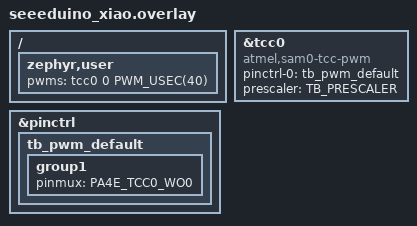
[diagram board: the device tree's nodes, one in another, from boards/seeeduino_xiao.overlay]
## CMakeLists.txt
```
# SPDX-License-Identifier: Apache-2.0

cmake_minimum_required(VERSION 3.20.0)
find_package(Zephyr REQUIRED HINTS $ENV{ZEPHYR_BASE})
project(sam0_tcc_pwm_testbench)

target_sources(app PRIVATE src/main.c src/tcc_util.c src/test_driver.c src/report.c)
target_sources_ifdef(CONFIG_TB_UF2_REBOOT app PRIVATE src/uf2_reboot.c)

# A testbench driver variant replaces the in-tree driver.
foreach(variant main lupd stop direct hybrid)
  string(TOUPPER ${variant} VARIANT)
  if(CONFIG_TB_DRIVER_${VARIANT})
    if(CONFIG_PWM_SAM0_TCC)
      message(FATAL_ERROR "Driver variant '${variant}' needs CONFIG_PWM_SAM0_TCC=n. "
                          "Build with -DEXTRA_CONF_FILE=variants/${variant}.conf.")
    endif()
    target_sources(app PRIVATE variants/pwm_sam0_tcc_${variant}.c)
  endif()
endforeach()

if(CONFIG_TB_DRIVER_IN_TREE AND NOT CONFIG_PWM_SAM0_TCC)
  message(FATAL_ERROR "The in-tree driver is selected, but CONFIG_PWM_SAM0_TCC is not set.")
endif()
```

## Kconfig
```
# SPDX-License-Identifier: Apache-2.0

mainmenu "SAM0 TCC PWM testbench"

choice TB_DRIVER
	prompt "PWM driver under test"
	default TB_DRIVER_IN_TREE

config TB_DRIVER_IN_TREE
	bool "drivers/pwm/pwm_sam0_tcc.c from ZEPHYR_BASE"

config TB_DRIVER_MAIN
	bool "Unpatched: write PERB/CCB directly (variants/pwm_sam0_tcc_main.c)"

config TB_DRIVER_LUPD
	bool "Hold CTRLB.LUPD across the PERB/CCB writes (variants/pwm_sam0_tcc_lupd.c)"

config TB_DRIVER_STOP
	bool "Stop the counter and write PER/CC directly (variants/pwm_sam0_tcc_stop.c)"

config TB_DRIVER_DIRECT
	bool "Write PER/CC directly on the running counter (variants/pwm_sam0_tcc_direct.c)"

config TB_DRIVER_HYBRID
	bool "Write PER directly, CC through CCB under LUPD (variants/pwm_sam0_tcc_hybrid.c)"

endchoice

config TB_SWEEP_TRIALS
	int "Trials for each starting period in the period sweep"
	default 100

config TB_DUTY_TRIALS
	int "Pulse-width changes in the duty test"
	default 200

config TB_UF2_REBOOT
	bool "Reboot into the UF2 bootloader when 'b' arrives on the console"
	default y if BOARD_SEEEDUINO_XIAO
	select REBOOT
	help
	  Lets a flash script enter the Adafruit UF2 bootloader without a
	  physical double-tap. The magic address is for 32 KB SRAM parts.

# udc_sam0.c logs every new IN transfer at INFO level. With a USB console,
# each console write logs another line, and the console floods. Show only
# USB driver warnings. This default applies only when USB is enabled.
choice UDC_DRIVER_LOG_LEVEL_CHOICE
	default UDC_DRIVER_LOG_LEVEL_WRN
endchoice

source "Kconfig.zephyr"
```

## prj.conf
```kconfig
CONFIG_ZTEST=y
# One summary line per suite; src/report.c prints the readable result
CONFIG_ZTEST_VERBOSE_SUMMARY=n
CONFIG_PWM=y
# The tests time TCC overflows with k_cycle_get_64().
CONFIG_CORTEX_M_SYSTICK_64BIT_CYCLE_COUNTER=y
# Preemptible test thread, so the USB stack and the UF2 reboot thread can
# run during a test. Measurements lock interrupts instead.
CONFIG_ZTEST_THREAD_PRIORITY=5
```

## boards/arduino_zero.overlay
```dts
/*
 * SPDX-License-Identifier: Apache-2.0
 *
 * Arduino Zero: TCC2/WO1 on PA17 (pin 13, LED), from the board's pwm-led0.
 * Each twister scenario sets the prescaler with -DTB_PRESCALER (see
 * testcase.yaml). A plain build uses prescaler 1.
 */

#include <zephyr/dt-bindings/pwm/pwm.h>

#ifndef TB_PRESCALER
#define TB_PRESCALER 1
#endif

/ {
	zephyr,user {
		pwms = <&tcc2 1 PWM_USEC(40)>;
	};
};

&tcc2 {
	prescaler = <TB_PRESCALER>;
};
```

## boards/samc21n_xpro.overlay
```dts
/*
 * SPDX-License-Identifier: Apache-2.0
 *
 * SAM C21N Xplained Pro: TCC2/WO1 on PC5 (LED0), from the board's pwm-led0.
 * Each twister scenario sets the prescaler with -DTB_PRESCALER (see
 * testcase.yaml). A plain build uses prescaler 1.
 */

#include <zephyr/dt-bindings/pwm/pwm.h>

#ifndef TB_PRESCALER
#define TB_PRESCALER 1
#endif

/ {
	zephyr,user {
		pwms = <&tcc2 1 PWM_USEC(40)>;
	};
};

&tcc2 {
	prescaler = <TB_PRESCALER>;
};
```

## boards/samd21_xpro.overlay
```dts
/*
 * SPDX-License-Identifier: Apache-2.0
 *
 * SAM D21 Xplained Pro: TCC0/WO0 on PB30 (LED0), from the board's pwm-led0.
 * Each twister scenario sets the prescaler with -DTB_PRESCALER (see
 * testcase.yaml). A plain build uses prescaler 1.
 */

#include <zephyr/dt-bindings/pwm/pwm.h>

#ifndef TB_PRESCALER
#define TB_PRESCALER 1
#endif

/ {
	zephyr,user {
		pwms = <&tcc0 0 PWM_USEC(40)>;
	};
};

&tcc0 {
	prescaler = <TB_PRESCALER>;
};
```

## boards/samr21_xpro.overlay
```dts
/*
 * SPDX-License-Identifier: Apache-2.0
 *
 * SAM R21 Xplained Pro: TCC0/WO3 on PA19 (LED0), from the board's pwm-led0.
 * Each twister scenario sets the prescaler with -DTB_PRESCALER (see
 * testcase.yaml). A plain build uses prescaler 1.
 */

#include <zephyr/dt-bindings/pwm/pwm.h>

#ifndef TB_PRESCALER
#define TB_PRESCALER 1
#endif

/ {
	zephyr,user {
		pwms = <&tcc0 3 PWM_USEC(40)>;
	};
};

&tcc0 {
	prescaler = <TB_PRESCALER>;
};
```

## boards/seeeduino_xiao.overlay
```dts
/*
 * SPDX-License-Identifier: Apache-2.0
 *
 * Seeeduino XIAO: TCC0/WO0 on PA4 (pin D1). No wiring needed.
 * Each twister scenario sets the prescaler with -DTB_PRESCALER (see
 * testcase.yaml). A plain build uses prescaler 1.
 */

#include <zephyr/dt-bindings/pwm/pwm.h>

#ifndef TB_PRESCALER
#define TB_PRESCALER 1
#endif

#include <dt-bindings/pinctrl/samd21-da1gXabcd-pinctrl.h>

&pinctrl {
	tb_pwm_default: tb_pwm_default {
		group1 {
			pinmux = <PA4E_TCC0_WO0>;
		};
	};
};

&tcc0 {
	status = "okay";
	compatible = "atmel,sam0-tcc-pwm";
	#pwm-cells = <2>;
	pinctrl-0 = <&tb_pwm_default>;
	pinctrl-names = "default";
};

/ {
	zephyr,user {
		pwms = <&tcc0 0 PWM_USEC(40)>;
	};
};

&tcc0 {
	prescaler = <TB_PRESCALER>;
};
```

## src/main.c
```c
/*
 * SPDX-License-Identifier: Apache-2.0
 *
 * SAM0 TCC PWM testbench. See README.md.
 */

#include <zephyr/kernel.h>
#include <zephyr/ztest.h>
#include <zephyr/drivers/uart.h>

#include "tb.h"

#define CONSOLE_NODE DT_CHOSEN(zephyr_console)

/*
 * A USB CDC ACM console drops output until the host opens the port. After
 * the port opens, wait 2 s more. A flash script that opened the port to
 * send 'b' then reboots this image before it starts a suite, so twister
 * does not record results from an image it is about to replace.
 */
static void wait_for_console(void)
{
#if DT_NODE_HAS_COMPAT(CONSOLE_NODE, zephyr_cdc_acm_uart) && defined(CONFIG_UART_LINE_CTRL)
	const struct device *cons = DEVICE_DT_GET(CONSOLE_NODE);
	uint32_t dtr = 0U;

	for (int i = 0; i < 300 && dtr == 0U; i++) {
		(void)uart_line_ctrl_get(cons, UART_LINE_CTRL_DTR, &dtr);
		k_msleep(100);
	}
	k_msleep(2000);
#endif
}

void test_main(void)
{
	wait_for_console();

	TC_PRINT("TB board=%s driver=%s prescaler=%u\n", CONFIG_BOARD_TARGET,
		 tb_driver_name(), TB_PRESCALER);
	TC_PRINT("TB %s\n", TB_FAMILY);
	TC_PRINT("TB tcc=0x%08x channel=%u counter_size=%u tcc_hz=%u cpu_hz=%u target=%u ticks\n",
		 (uint32_t)(uintptr_t)tb_tcc, tb_spec.channel, TB_COUNTER_SIZE,
		 (uint32_t)tb_tcc_hz(), (uint32_t)tb_cpu_hz(), tb_target_period());

	ztest_run_all(NULL, false, 1, 1);
	tb_report();
	ztest_verify_all_test_suites_ran();
}
```

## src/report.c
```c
/*
 * SPDX-License-Identifier: Apache-2.0
 *
 * Final report: one plain-language block per run, then one TBSUM line
 * that scripts/summarize.py collects into a table across runs.
 */

#include <stdlib.h>
#include <zephyr/kernel.h>
#include <zephyr/sys/printk.h>

#include "tb.h"

enum verdict {
	GOOD,
	NOT_GLITCH_FREE,
	BROKEN,
	INCOMPLETE,
};

static const char *const verdict_text[] = {
	[GOOD] = "GOOD - every update took effect, and updates are glitch-free",
	[NOT_GLITCH_FREE] = "WORKS, NOT GLITCH-FREE - every update took effect, "
			    "but updates disturb the PWM cycle",
	[BROKEN] = "BROKEN - some updates did not take effect",
	[INCOMPLETE] = "INCOMPLETE - a test did not finish; see the ztest output",
};

static const char *const verdict_tag[] = {
	[GOOD] = "GOOD",
	[NOT_GLITCH_FREE] = "NOT_GLITCH_FREE",
	[BROKEN] = "BROKEN",
	[INCOMPLETE] = "INCOMPLETE",
};

static uint32_t sweep_lost_total(void)
{
	uint32_t total = 0U;

	for (uint32_t i = 0; i < tb_res.sweep_count; i++) {
		total += tb_res.sweep_lost[i];
	}
	return total;
}

static bool glitch_ok(void)
{
	return tb_res.glitch_delta_cpu <= tb_res.glitch_limit_cpu &&
	       tb_res.glitch_delta_cpu >= -tb_res.glitch_limit_cpu;
}

static enum verdict get_verdict(void)
{
	if ((tb_res.boot_ran && !tb_res.boot_ok) ||
	    (tb_res.sweep_ran && sweep_lost_total() != 0U) ||
	    (tb_res.shrink_ran && tb_res.shrink_failed != 0U) ||
	    (tb_res.duty_ran && tb_res.duty_lost != 0U)) {
		return BROKEN;
	}
	if (!tb_res.boot_ran || !tb_res.sweep_ran || !tb_res.shrink_ran || !tb_res.glitch_ran ||
	    !tb_res.duty_ran) {
		return INCOMPLETE;
	}
	return (glitch_ok() && tb_res.duty_skipped == 0U) ? GOOD : NOT_GLITCH_FREE;
}

static const char *yes_no(bool ran, bool ok)
{
	return !ran ? "not run" : (ok ? "yes" : "NO");
}

void tb_report(void)
{
	const uint32_t sweep_total = tb_res.sweep_count * tb_res.sweep_trials;
	const uint32_t cpu_mhz = (uint32_t)(tb_cpu_hz() / 1000000U);
	enum verdict v = get_verdict();

	printk("\n================ RESULT ================\n");
	printk("Board:      %s\n", CONFIG_BOARD_TARGET);
	printk("Driver:     %s\n", tb_driver_name());
	printk("Prescaler:  %u (target period %u ticks)\n", TB_PRESCALER, tb_target_period());
	printk("\n");

	printk("Works after boot:      %s\n", yes_no(tb_res.boot_ran, tb_res.boot_ok));

	if (tb_res.sweep_ran) {
		printk("Period changes lost:   %u of %u\n", sweep_lost_total(), sweep_total);
		printk("  by starting PER:    ");
		for (uint32_t i = 0; i < tb_res.sweep_count; i++) {
			printk(" %u:%u", tb_res.sweep_start[i], tb_res.sweep_lost[i]);
		}
		printk("  (of %u each)\n", tb_res.sweep_trials);
	} else {
		printk("Period changes lost:   not run\n");
	}

	if (tb_res.shrink_ran) {
		printk("Shorter period works:  %-8s (starts after %u us, limit %u us)\n",
		       tb_res.shrink_failed == 0U ? "yes" : "NO", tb_res.shrink_worst_us,
		       tb_res.shrink_limit_us);
	} else {
		printk("Shorter period works:  not run\n");
	}

	if (tb_res.glitch_ran) {
		uint32_t mag = (uint32_t)abs(tb_res.glitch_delta_cpu);

		printk("Glitch-free updates:   %-8s (each update stretches the PWM cycle by "
		       "%d CPU cycles, %s%u.%02u us)\n",
		       glitch_ok() ? "yes" : "NO", tb_res.glitch_delta_cpu,
		       tb_res.glitch_delta_cpu < 0 ? "-" : "", mag / cpu_mhz,
		       (mag % cpu_mhz) * 100U / cpu_mhz);
	} else {
		printk("Glitch-free updates:   not run\n");
	}

	if (tb_res.duty_ran) {
		printk("Duty changes lost:     %u of %u (", tb_res.duty_lost, tb_res.duty_trials);
		if (tb_res.duty_period_short < tb_res.duty_period_normal) {
			printk("periods %u and %u ticks", tb_res.duty_period_normal,
			       tb_res.duty_period_short);
		} else {
			printk("period %u ticks", tb_res.duty_period_normal);
		}
		printk("; %u trials not judged)\n", tb_res.duty_overran);
		printk("Skipped matches:       %u of %u (cycles with the output on for the "
		       "whole cycle)\n", tb_res.duty_skipped, tb_res.duty_trials);
	} else {
		printk("Duty changes lost:     not run\n");
	}

	printk("\nVERDICT: %s\n", verdict_text[v]);
	printk("========================================\n");

	/* One line for scripts/summarize.py */
	printk("TBSUM board=%s prescaler=%u driver=%s boot=%s period_lost=%u/%u "
	       "shrink_us=%u glitch_cpu=%d duty_lost=%u/%u skipped=%u/%u verdict=%s\n",
	       CONFIG_BOARD_TARGET, TB_PRESCALER, tb_driver_name(),
	       !tb_res.boot_ran ? "-" : (tb_res.boot_ok ? "ok" : "FAIL"), sweep_lost_total(),
	       sweep_total, tb_res.shrink_worst_us, tb_res.glitch_delta_cpu, tb_res.duty_lost,
	       tb_res.duty_trials, tb_res.duty_skipped, tb_res.duty_trials, verdict_tag[v]);
}
```

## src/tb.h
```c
/*
 * SPDX-License-Identifier: Apache-2.0
 *
 * Shared definitions for the SAM0 TCC PWM testbench.
 */

#ifndef TB_H_
#define TB_H_

#include <stdbool.h>
#include <stdint.h>
#include <zephyr/devicetree.h>
#include <zephyr/drivers/pwm.h>
#include <soc.h>

#define TB_USER_NODE DT_PATH(zephyr_user)

#if !DT_NODE_HAS_PROP(TB_USER_NODE, pwms)
#error "Add a zephyr,user node with a pwms property (see README.md)"
#endif

#define TB_TCC_NODE     DT_PWMS_CTLR(TB_USER_NODE)
#define TB_PRESCALER    DT_PROP(TB_TCC_NODE, prescaler)
#define TB_COUNTER_SIZE DT_PROP(TB_TCC_NODE, counter_size)

/* Register name differences between the SAMD21 TCC and later revisions */
#ifdef TCC_PERBUF_PERBUF
#define TB_STATUS_PERBV     TCC_STATUS_PERBUFV
#define TB_STATUS_CCBV(ch)  TCC_STATUS_CCBUFV(BIT(ch))
#define TB_FAMILY           "PERBUF/CCBUF branch (SAMC2x/SAML2x/SAMD5x/SAME5x/SAMR3x)"
#else
#define TB_STATUS_PERBV     TCC_STATUS_PERBV
#define TB_STATUS_CCBV(ch)  TCC_STATUS_CCBV(BIT(ch))
#define TB_FAMILY           "PERB/CCB branch (SAMD21/SAMR21)"
#endif

extern const struct pwm_dt_spec tb_spec;
extern Tcc *const tb_tcc;

const char *tb_driver_name(void);

/* CPU cycle clock (k_cycle_get_64() units) and TCC tick rate, in Hz */
uint64_t tb_cpu_hz(void);
uint64_t tb_tcc_hz(void);

/* Convert TCC ticks to CPU cycles */
uint64_t tb_ticks_to_cpu(uint64_t ticks);

/*
 * Period that the tests request, in TCC ticks. At least 53 ticks, and at
 * least 1920 CPU cycles, so the overflow poll can time it accurately:
 * 1920 ticks (40 us) at prescaler 1, 53 ticks (1.1 ms) at prescaler 1024.
 */
uint32_t tb_target_period(void);

/* Deterministic pseudo-random numbers, so a failing run can be repeated */
uint32_t tb_rand(void);
void tb_rand_seed(uint32_t seed);

/*
 * Random delay of 0 to at least span_cpu CPU cycles, in single-cycle steps.
 * The CPU and the TCC can share a clock, so a delay loop alone reaches
 * only phases that are multiples of its iteration time. A run of 0 to 15
 * NOPs fills in the gaps.
 */
void tb_dither(uint32_t span_cpu);

void tb_wait_sync(void);

/*
 * Put the TCC in a known state without the driver: stop the counter,
 * write PER directly, clear COUNT and stale buffer-valid flags, restart.
 * The driver cannot reach a short period reliably, which is the bug
 * under test, so the tests use this instead.
 */
void tb_force_period(uint32_t per);

/*
 * Average period in CPU cycles over n overflows, timed from INTFLAG.OVF.
 * Returns 0 if an overflow takes more than 250 ms. Interrupts are locked
 * during the measurement.
 */
uint64_t tb_measure_period(uint32_t n);

/*
 * True if a measured period matches period_ticks within 2%. NPWM counts
 * PER + 1 ticks; the driver writes PER = period_ticks.
 */
bool tb_period_ok(uint64_t measured_cpu, uint32_t period_ticks);

/*
 * Wait for an INTFLAG flag. Returns the time in CPU cycles, or 0 on a
 * timeout. Clears the flag first if clear_first is true, and always
 * clears it when it sets. The poll is the same for every flag, so two
 * timestamps have the same delay.
 */
uint64_t tb_wait_flag(uint32_t mask, bool clear_first, uint64_t timeout_cpu);

/* tb_wait_flag() for the overflow flag INTFLAG.OVF */
uint64_t tb_wait_ovf(bool clear_first, uint64_t timeout_cpu);

/* Results that the tests record for the final report (src/report.c) */
#define TB_MAX_STARTS 10

struct tb_results {
	bool boot_ran;
	bool boot_ok;

	bool sweep_ran;
	uint32_t sweep_count;
	uint32_t sweep_start[TB_MAX_STARTS];
	uint32_t sweep_lost[TB_MAX_STARTS];
	uint32_t sweep_trials; /* for each start */

	bool shrink_ran;
	uint32_t shrink_worst_us;
	uint32_t shrink_limit_us;
	uint32_t shrink_failed;
	uint32_t shrink_trials;

	bool glitch_ran;
	int32_t glitch_delta_cpu; /* added to each period by an update */
	int32_t glitch_limit_cpu;

	bool duty_ran;
	uint32_t duty_period_normal; /* ticks */
	uint32_t duty_period_short;  /* ticks */
	uint32_t duty_overran;       /* trials the test could not judge */
	uint32_t duty_trials;        /* trials judged */
	uint32_t duty_lost;    /* the new pulse width did not take effect */
	uint32_t duty_skipped; /* a cycle had no compare match: output on all cycle */
};

extern struct tb_results tb_res;

/* Print the summary block. test_main() calls it after all suites run. */
void tb_report(void);

#endif /* TB_H_ */
```

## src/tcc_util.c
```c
/*
 * SPDX-License-Identifier: Apache-2.0
 *
 * Register access and measurement helpers. All chip details come from
 * devicetree and the HAL headers, so the same code runs on every TCC
 * revision and at every prescaler.
 */

#include <zephyr/kernel.h>
#include <zephyr/sys/util.h>

#include "tb.h"

const struct pwm_dt_spec tb_spec = PWM_DT_SPEC_GET(TB_USER_NODE);
Tcc *const tb_tcc = (Tcc *)DT_REG_ADDR(TB_TCC_NODE);

static uint32_t rand_state = 0x2545F491U;

const char *tb_driver_name(void)
{
	if (IS_ENABLED(CONFIG_TB_DRIVER_MAIN)) {
		return "main";
	} else if (IS_ENABLED(CONFIG_TB_DRIVER_LUPD)) {
		return "lupd";
	} else if (IS_ENABLED(CONFIG_TB_DRIVER_STOP)) {
		return "stop";
	} else if (IS_ENABLED(CONFIG_TB_DRIVER_DIRECT)) {
		return "direct";
	} else if (IS_ENABLED(CONFIG_TB_DRIVER_HYBRID)) {
		return "hybrid";
	}
	return "in_tree";
}

uint64_t tb_cpu_hz(void)
{
	return sys_clock_hw_cycles_per_sec();
}

uint64_t tb_tcc_hz(void)
{
	uint64_t hz = 0U;

	(void)pwm_get_cycles_per_sec(tb_spec.dev, tb_spec.channel, &hz);
	__ASSERT_NO_MSG(hz != 0U);
	return hz;
}

uint64_t tb_ticks_to_cpu(uint64_t ticks)
{
	uint64_t tcc_hz = tb_tcc_hz();

	return tcc_hz != 0U ? ticks * tb_cpu_hz() / tcc_hz : 0U;
}

uint32_t tb_target_period(void)
{
	uint64_t cpu_per_tick = MAX(tb_cpu_hz() / tb_tcc_hz(), 1U);

	return MAX(53U, (uint32_t)DIV_ROUND_UP(1920U, cpu_per_tick));
}

uint32_t tb_rand(void)
{
	/* xorshift32 */
	rand_state ^= rand_state << 13;
	rand_state ^= rand_state >> 17;
	rand_state ^= rand_state << 5;
	return rand_state;
}

void tb_rand_seed(uint32_t seed)
{
	rand_state = (seed != 0U) ? seed : 1U;
}

static void spin(uint32_t n)
{
	for (volatile uint32_t i = 0; i < n; i++) {
	}
}

void tb_dither(uint32_t span_cpu)
{
	uint32_t r = tb_rand();

	/* One loop pass takes more than 4 CPU cycles, so this covers span_cpu */
	spin((r >> 4) % (span_cpu / 4U + 1U));

	/* Enter the NOP run at a random point: 0 to 15 single-cycle steps */
	switch (r & 0xFU) {
	case 15: arch_nop(); __fallthrough;
	case 14: arch_nop(); __fallthrough;
	case 13: arch_nop(); __fallthrough;
	case 12: arch_nop(); __fallthrough;
	case 11: arch_nop(); __fallthrough;
	case 10: arch_nop(); __fallthrough;
	case 9: arch_nop(); __fallthrough;
	case 8: arch_nop(); __fallthrough;
	case 7: arch_nop(); __fallthrough;
	case 6: arch_nop(); __fallthrough;
	case 5: arch_nop(); __fallthrough;
	case 4: arch_nop(); __fallthrough;
	case 3: arch_nop(); __fallthrough;
	case 2: arch_nop(); __fallthrough;
	case 1: arch_nop(); __fallthrough;
	default:
		break;
	}
}

void tb_wait_sync(void)
{
	while (tb_tcc->SYNCBUSY.reg != 0U) {
	}
}

void tb_force_period(uint32_t per)
{
	tb_tcc->CTRLA.bit.ENABLE = 0;
	tb_wait_sync();
	tb_tcc->PER.reg = per;
	tb_tcc->CC[tb_spec.channel].reg = per / 2U;
	tb_tcc->COUNT.reg = 0U;
	tb_wait_sync();
	tb_tcc->STATUS.reg = TB_STATUS_PERBV | TB_STATUS_CCBV(tb_spec.channel);
	tb_tcc->CTRLA.bit.ENABLE = 1;
	tb_wait_sync();
}

uint64_t tb_wait_flag(uint32_t mask, bool clear_first, uint64_t timeout_cpu)
{
	uint64_t deadline = k_cycle_get_64() + timeout_cpu;
	uint32_t n = 0U;

	if (clear_first) {
		tb_tcc->INTFLAG.reg = mask;
	}
	while ((tb_tcc->INTFLAG.reg & mask) == 0U) {
		/* Read the clock only now and then, to keep the poll tight */
		if ((++n & 0xFFU) == 0U && k_cycle_get_64() > deadline) {
			return 0U;
		}
	}
	tb_tcc->INTFLAG.reg = mask;
	return k_cycle_get_64();
}

uint64_t tb_wait_ovf(bool clear_first, uint64_t timeout_cpu)
{
	return tb_wait_flag(TCC_INTFLAG_OVF, clear_first, timeout_cpu);
}

uint64_t tb_measure_period(uint32_t n)
{
	/* Under the SysTick wrap (about 349 ms), so the lock stays safe */
	uint64_t timeout = tb_cpu_hz() / 4U;
	uint64_t t0;
	uint64_t t1 = 0U;
	unsigned int key;

	/* An ISR at t0 or t1 would skew the result; keep them out */
	key = irq_lock();

	/* Discard any stale flag, then start timing on a fresh overflow */
	t0 = tb_wait_ovf(true, timeout);
	for (uint32_t i = 0; i < n && t0 != 0U; i++) {
		t1 = tb_wait_ovf(false, timeout);
		if (t1 == 0U) {
			t0 = 0U;
		}
	}

	irq_unlock(key);
	return (t0 != 0U) ? (t1 - t0) / n : 0U;
}

bool tb_period_ok(uint64_t measured_cpu, uint32_t period_ticks)
{
	uint64_t expected = tb_ticks_to_cpu((uint64_t)period_ticks + 1U);
	uint64_t tol = expected / 50U;

	return measured_cpu + tol >= expected && measured_cpu <= expected + tol;
}
```

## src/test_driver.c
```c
/*
 * SPDX-License-Identifier: Apache-2.0
 *
 * Driver tests. These call only the PWM API, and judge the result by
 * timing the TCC's own overflow flag. README.md, "How the defect is
 * detected", describes each test step by step. All periods and delays scale with
 * the TCC tick, so the tests run at any prescaler. Each test records its
 * numbers in tb_res for the final report (src/report.c).
 *
 * ztest runs suites in name order, so the boot test runs before anything
 * else touches the timer.
 */

#include <zephyr/kernel.h>
#include <zephyr/ztest.h>

#include "tb.h"

#define SHRINK_TRIALS 10U

/* Longest time with interrupts locked in one measurement */
#define MAX_LOCK_MS 50U

struct tb_results tb_res;

static int set_period(uint32_t period, uint32_t pulse)
{
	return pwm_set_cycles(tb_spec.dev, tb_spec.channel, period, pulse, 0);
}

/* Number of periods that fit in MAX_LOCK_MS, within [lo, hi] */
static uint32_t periods_in_lock(uint32_t period_ticks, uint32_t lo, uint32_t hi)
{
	uint64_t period_cpu = tb_ticks_to_cpu(period_ticks + 1U);
	uint64_t n = tb_cpu_hz() * MAX_LOCK_MS / 1000U / period_cpu;

	return CLAMP((uint32_t)n, lo, hi);
}

/* Wait long enough for a buffered update to land: two periods plus margin */
static void settle(uint32_t period_ticks)
{
	uint64_t us = tb_ticks_to_cpu(2U * (period_ticks + 1U)) * 1000000U / tb_cpu_hz();

	k_busy_wait((uint32_t)us + 20U);
}

/*
 * Tests that act inside each PWM cycle (glitch and duty) must finish their
 * work before the next overflow, or they miss an overflow. They use a
 * period of at least CYCLE_MIN_CPU CPU cycles.
 */
#define CYCLE_MIN_CPU 8000U

static uint32_t slow_period(void)
{
	uint32_t cpu_per_tick = MAX((uint32_t)(tb_cpu_hz() / tb_tcc_hz()), 1U);

	return MAX(tb_target_period(), DIV_ROUND_UP(CYCLE_MIN_CPU, cpu_per_tick));
}

static void *suite_setup(void)
{
	zassert_true(pwm_is_ready_dt(&tb_spec), "PWM device not ready");
	tb_rand_seed(0x5A4D3231U);
	return NULL;
}

/*
 * The first pwm_set() after boot. The unpatched SAMD21 driver starts at
 * PER = 1, where most PERB writes are lost.
 */
ZTEST(tcc_1_boot, test_works_after_boot)
{
	const uint32_t target = tb_target_period();
	uint64_t period;

	zassert_ok(set_period(target, target / 2U));
	settle(target);
	period = tb_measure_period(periods_in_lock(target, 4U, 32U));

	tb_res.boot_ran = true;
	tb_res.boot_ok = tb_period_ok(period, target);

	zassert_true(tb_res.boot_ok, "the first pwm_set() did not set the period");
}

ZTEST_SUITE(tcc_1_boot, NULL, suite_setup, NULL, NULL, NULL);

/*
 * From each starting period, request the target period at a random point
 * in the counter cycle and check that it takes effect. The loss
 * probability falls as the starting period grows.
 */
ZTEST(tcc_2_period, test_period_changes)
{
	static const uint32_t starts[TB_MAX_STARTS] = {1, 2, 3, 4, 5, 8, 16, 32, 256, 1000};
	const uint32_t target = tb_target_period();
	const uint32_t n_meas = periods_in_lock(target, 4U, 16U);
	uint32_t total = 0U;
	uint32_t count = 0U;

	tb_res.sweep_ran = true;
	tb_res.sweep_trials = CONFIG_TB_SWEEP_TRIALS;

	for (size_t s = 0; s < ARRAY_SIZE(starts); s++) {
		/* Keep starts well away from the target, so a loss is visible */
		if (starts[s] > target * 9U / 10U) {
			continue;
		}

		uint32_t span = (uint32_t)tb_ticks_to_cpu(starts[s] + 1U);
		uint32_t lost = 0U;

		for (uint32_t t = 0; t < CONFIG_TB_SWEEP_TRIALS; t++) {
			tb_force_period(starts[s]);
			tb_dither(span);
			zassert_ok(set_period(target, target / 2U));
			settle(starts[s]);
			if (!tb_period_ok(tb_measure_period(n_meas), target)) {
				lost++;
			}
		}
		tb_res.sweep_start[count] = starts[s];
		tb_res.sweep_lost[count] = lost;
		count++;
		total += lost;
	}
	tb_res.sweep_count = count;

	zassert_equal(total, 0U, "%u of %u period changes lost", total,
		      count * CONFIG_TB_SWEEP_TRIALS);
}

ZTEST_SUITE(tcc_2_period, NULL, suite_setup, NULL, NULL, NULL);

/*
 * Change to a shorter period while COUNT is above the new period. A
 * buffered update lands at the end of the current period. A direct PER
 * write that keeps COUNT lets the counter run to the wrap: up to 0.35 s
 * on a 24-bit TCC at prescaler 1.
 */
ZTEST(tcc_3_shrink, test_shorter_period)
{
	const uint32_t target = tb_target_period();
	const uint32_t big = MIN(target * 16U, (uint32_t)BIT(TB_COUNTER_SIZE) / 2U);
	const uint64_t big_cpu = tb_ticks_to_cpu(big + 1U);
	const uint64_t allowed = big_cpu / 4U + tb_ticks_to_cpu(2U * (target + 1U));
	const uint64_t timeout = tb_cpu_hz() / 4U;
	uint64_t worst = 0U;
	uint32_t failed = 0U;

	for (uint32_t t = 0; t < SHRINK_TRIALS; t++) {
		uint64_t t_ovf;
		uint64_t t_set;
		uint64_t t_first;
		uint64_t latency;
		bool period_ok;

		tb_force_period(big);
		zassert_true(tb_period_ok(tb_measure_period(2), big), "start state");

		/*
		 * Write at 80% of the period, so COUNT is above the new period.
		 * Interrupts are locked, so an ISR or a higher-priority thread
		 * cannot delay the timestamps. The wait for the first overflow
		 * stops at twice the limit; a later overflow fails anyway.
		 */
		unsigned int key = irq_lock();

		t_ovf = tb_wait_ovf(true, timeout);
		while (k_cycle_get_64() < t_ovf + big_cpu * 8U / 10U) {
		}
		tb_tcc->INTFLAG.reg = TCC_INTFLAG_OVF;
		(void)set_period(target, target / 2U);
		t_set = k_cycle_get_64();
		t_first = tb_wait_ovf(false, 2U * allowed);
		irq_unlock(key);

		latency = (t_first != 0U) ? t_first - t_set : 2U * allowed;
		period_ok = tb_period_ok(tb_measure_period(periods_in_lock(target, 4U, 8U)),
					 target);

		worst = MAX(worst, latency);
		if (latency > allowed || !period_ok) {
			failed++;
		}
	}

	tb_res.shrink_ran = true;
	tb_res.shrink_worst_us = (uint32_t)(worst * 1000000U / tb_cpu_hz());
	tb_res.shrink_limit_us = (uint32_t)(allowed * 1000000U / tb_cpu_hz());
	tb_res.shrink_failed = failed;
	tb_res.shrink_trials = SHRINK_TRIALS;

	zassert_equal(failed, 0U, "the new period was late or wrong in %u of %u trials",
		      failed, SHRINK_TRIALS);
}

ZTEST_SUITE(tcc_3_shrink, NULL, suite_setup, NULL, NULL, NULL);

/*
 * Call pwm_set() with unchanged values once per period, at a random point
 * in the first half of the cycle. A glitch-free driver leaves the counter
 * alone, so the average period stays the same. A driver that stops or
 * restarts the counter makes it longer. A restart disturbs every channel
 * of the TCC.
 *
 * The test fails with a clear message if it misses an overflow, so a slow
 * loop cannot show up as a false stretch.
 */
ZTEST(tcc_4_glitch, test_glitch_free)
{
	const uint32_t period = slow_period();
	const uint32_t n = periods_in_lock(period, 16U, 256U);
	const uint32_t period_cpu = (uint32_t)tb_ticks_to_cpu(period + 1U);
	const uint64_t timeout = tb_cpu_hz() / 4U;
	const int64_t limit = 64;
	uint64_t base;
	uint64_t t0;
	uint64_t t;
	uint64_t longest = 0U;
	int64_t delta;
	unsigned int key;

	tb_force_period(period);
	base = tb_measure_period(n);
	zassert_true(tb_period_ok(base, period), "start state");

	key = irq_lock();
	t0 = tb_wait_ovf(true, timeout);
	t = t0;
	for (uint32_t i = 0; i < n && t != 0U; i++) {
		uint64_t prev = t;
		uint64_t at = t + tb_rand() % (period_cpu / 2U);

		while (k_cycle_get_64() < at) {
		}
		(void)set_period(period, period / 2U);
		t = tb_wait_ovf(false, timeout);
		if (t != 0U) {
			longest = MAX(longest, t - prev);
		}
	}
	irq_unlock(key);
	zassert_true(t0 != 0U && t != 0U, "counter stopped");

	/* A restart adds less than one period; 1.8 periods means a missed overflow */
	zassert_true(longest < base * 18U / 10U,
		     "test overran: missed an overflow (longest gap %u CPU cycles, period %u)",
		     (uint32_t)longest, (uint32_t)base);

	delta = (int64_t)((t - t0) / n) - (int64_t)base;

	tb_res.glitch_ran = true;
	tb_res.glitch_delta_cpu = (int32_t)delta;
	tb_res.glitch_limit_cpu = (int32_t)limit;

	zassert_true(delta <= limit && delta >= -limit,
		     "each update stretches the PWM cycle by %d CPU cycles", (int32_t)delta);
}

ZTEST_SUITE(tcc_4_glitch, NULL, suite_setup, NULL, NULL, NULL);

/*
 * Change only the pulse width, at a random point in the first 75% of the
 * cycle. The pulse alternates between 3/4 and 1/4 of the period, so every
 * second change is a decrease. The test runs at two periods: a normal one,
 * and the shortest one the per-cycle measurement can follow, where update
 * conditions are frequent.
 *
 * In NPWM mode the output goes low at the compare match (COUNT == CC).
 * If a driver writes a lower CC directly after COUNT has passed it, but
 * before the old match, that cycle has no match. The output then stays
 * on for the whole cycle. The test detects this with the match flag
 * INTFLAG.MCx: no match between two overflows is a skipped match.
 *
 * The test also times the next full cycle, from overflow to match. If
 * that time does not fit the new pulse width, the write was lost.
 *
 * If the cycle ends while the driver call runs, the test cannot judge
 * that trial and skips it. A driver that restarts the counter does not
 * set the overflow flag, so a restart is judged normally.
 */
struct duty_counts {
	uint32_t judged;
	uint32_t lost;
	uint32_t skipped;
	uint32_t overran;
};

static void duty_trials(uint32_t period, struct duty_counts *c)
{
	const uint32_t hi = period * 3U / 4U;
	const uint32_t lo = period / 4U;
	const uint32_t period_cpu = (uint32_t)tb_ticks_to_cpu(period + 1U);
	/* A lost write leaves the old width, (hi - lo) away */
	const uint64_t tol = tb_ticks_to_cpu((hi - lo) / 4U);
	const uint32_t mc = BIT(TCC_INTFLAG_MC_Pos + tb_spec.channel);
	const uint64_t timeout = tb_cpu_hz() / 4U;
	bool printed = false;

	tb_force_period(period);
	zassert_ok(set_period(period, hi));
	settle(period);

	for (uint32_t t = 0; t < CONFIG_TB_DUTY_TRIALS; t++) {
		const uint32_t pulse = (t & 1U) ? hi : lo;
		uint64_t t_ovf;
		uint64_t t_end;
		uint64_t t_match = 0U;
		unsigned int key;
		bool matched;
		bool late;

		key = irq_lock();

		/* Start of the cycle that the update lands in */
		t_ovf = tb_wait_ovf(true, timeout);
		tb_tcc->INTFLAG.reg = mc;

		/* Update somewhere in the first 75% of the cycle */
		uint64_t at = t_ovf + tb_rand() % (period_cpu * 3U / 4U);

		while (k_cycle_get_64() < at) {
		}
		(void)set_period(period, pulse);

		/* An overflow during the driver call means the cycle ended early */
		late = (tb_tcc->INTFLAG.reg & TCC_INTFLAG_OVF) != 0U;

		/* End of that cycle: was there a compare match in it? */
		t_end = tb_wait_ovf(false, timeout);
		matched = (tb_tcc->INTFLAG.reg & mc) != 0U;
		tb_tcc->INTFLAG.reg = mc;

		/* The next full cycle: time from overflow to match */
		if (t_end != 0U) {
			t_match = tb_wait_flag(mc, false, 2U * period_cpu);
		}

		irq_unlock(key);

		zassert_true(t_ovf != 0U && t_end != 0U, "counter stopped");

		if (late) {
			c->overran++;
			continue;
		}
		c->judged++;

		uint64_t expected = tb_ticks_to_cpu(pulse);
		uint64_t width = (t_match != 0U) ? t_match - t_end : 0U;

		if (!matched) {
			c->skipped++;
		}
		if (t_match == 0U || width + tol < expected || width > expected + tol) {
			c->lost++;
			if (!printed) {
				TC_PRINT("first lost pulse change at period %u: expected %u CPU "
					 "cycles, measured %u\n", period, (uint32_t)expected,
					 (uint32_t)width);
				printed = true;
			}
		}
	}
}

ZTEST(tcc_5_duty, test_duty_changes)
{
	const uint32_t cpu_per_tick = MAX((uint32_t)(tb_cpu_hz() / tb_tcc_hz()), 1U);
	const uint32_t normal = slow_period();
	const uint32_t shortest = MAX(8U, DIV_ROUND_UP(CYCLE_MIN_CPU, cpu_per_tick));
	struct duty_counts c = {0};

	duty_trials(normal, &c);
	if (shortest < normal) {
		duty_trials(shortest, &c);
	}

	tb_res.duty_ran = true;
	tb_res.duty_period_normal = normal;
	tb_res.duty_period_short = MIN(shortest, normal);
	tb_res.duty_trials = c.judged;
	tb_res.duty_lost = c.lost;
	tb_res.duty_skipped = c.skipped;
	tb_res.duty_overran = c.overran;

	zassert_true(c.judged >= c.overran,
		     "test overran: only %u trials could be judged, %u could not",
		     c.judged, c.overran);
	zassert_equal(c.lost, 0U, "%u of %u pulse-width changes lost", c.lost, c.judged);
	zassert_equal(c.skipped, 0U, "%u of %u changes gave a cycle with no compare match",
		      c.skipped, c.judged);
}

ZTEST_SUITE(tcc_5_duty, NULL, suite_setup, NULL, NULL, NULL);
```

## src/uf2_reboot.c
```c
/*
 * SPDX-License-Identifier: Apache-2.0
 *
 * Reboot into the Adafruit UF2 bootloader when 'b' arrives on the
 * console. scripts/uf2_flash.sh uses this to flash without a physical
 * double-tap.
 */

#include <zephyr/kernel.h>
#include <zephyr/drivers/uart.h>
#include <zephyr/sys/reboot.h>
#include <zephyr/sys/sys_io.h>

/* Double-tap magic in the last word of a 32 KB SRAM */
#define DBL_TAP_PTR   0x20007FFCUL
#define DBL_TAP_MAGIC 0xF01669EFUL

static void uf2_reboot_thread(void *p1, void *p2, void *p3)
{
	const struct device *cons = DEVICE_DT_GET(DT_CHOSEN(zephyr_console));
	unsigned char ch;

	ARG_UNUSED(p1);
	ARG_UNUSED(p2);
	ARG_UNUSED(p3);

	while (true) {
		while (uart_poll_in(cons, &ch) == 0) {
			if (ch == 'b') {
				sys_write32(DBL_TAP_MAGIC, DBL_TAP_PTR);
				sys_reboot(SYS_REBOOT_COLD);
			}
		}
		k_msleep(50);
	}
}

/*
 * Higher priority than the test thread (CONFIG_ZTEST_THREAD_PRIORITY), so
 * a flash script can stop a running suite. Measurements lock interrupts,
 * so this thread cannot disturb them.
 */
BUILD_ASSERT(CONFIG_ZTEST_THREAD_PRIORITY > 1, "test thread must be preemptible");
K_THREAD_DEFINE(uf2_reboot, 512, uf2_reboot_thread, NULL, NULL, NULL, 1, 0, 0);
```
